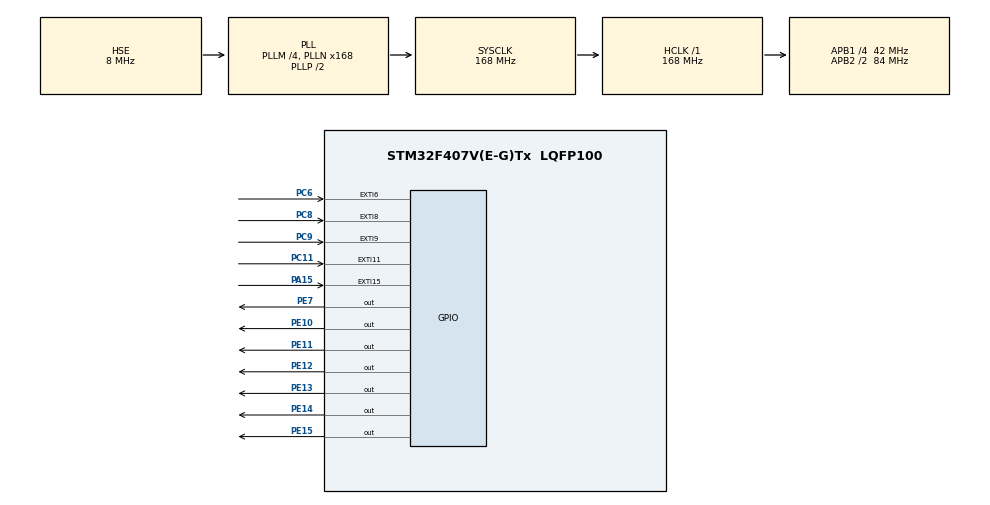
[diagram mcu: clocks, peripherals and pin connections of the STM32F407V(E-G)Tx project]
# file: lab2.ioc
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Mcu.Family=STM32F4
Mcu.Name=STM32F407V(E-G)Tx
Mcu.Package=LQFP100
NVIC.EXTI15_10_IRQn=true\:0\:0\:false\:false\:true\:true\:true
NVIC.EXTI9_5_IRQn=true\:0\:0\:false\:false\:true\:true\:true
NVIC.PriorityGroup=NVIC_PRIORITYGROUP_4
PA15.GPIO_ModeDefaultEXTI=GPIO_MODE_IT_FALLING
PA15.Signal=GPXTI15
PC11.GPIO_ModeDefaultEXTI=GPIO_MODE_IT_FALLING
PC11.Signal=GPXTI11
PC6.GPIO_ModeDefaultEXTI=GPIO_MODE_IT_FALLING
PC6.Signal=GPXTI6
PC8.GPIO_ModeDefaultEXTI=GPIO_MODE_IT_FALLING
PC8.Signal=GPXTI8
PC9.GPIO_ModeDefaultEXTI=GPIO_MODE_IT_FALLING
PC9.Signal=GPXTI9
PE10.Signal=GPIO_Output
PE11.Signal=GPIO_Output
PE12.Signal=GPIO_Output
PE13.Signal=GPIO_Output
PE14.Signal=GPIO_Output
PE15.Signal=GPIO_Output
PE7.Signal=GPIO_Output
PH0-OSC_IN.Mode=HSE-External-Oscillator
PH0-OSC_IN.Signal=RCC_OSC_IN
PH1-OSC_OUT.Mode=HSE-External-Oscillator
PH1-OSC_OUT.Signal=RCC_OSC_OUT
ProjectManager.HeapSize=0x200
ProjectManager.StackSize=0x400
ProjectManager.TargetToolchain=MDK-ARM V5.27
RCC.48MHZClocksFreq_Value=84000000
RCC.AHBFreq_Value=168000000
RCC.APB1CLKDivider=RCC_HCLK_DIV4
RCC.APB1Freq_Value=42000000
RCC.APB1TimFreq_Value=84000000
RCC.APB2CLKDivider=RCC_HCLK_DIV2
RCC.APB2Freq_Value=84000000
RCC.APB2TimFreq_Value=168000000
RCC.CortexFreq_Value=168000000
RCC.HCLKFreq_Value=168000000
RCC.HSE_VALUE=8000000
RCC.HSI_VALUE=16000000
RCC.LSE_VALUE=32768
RCC.PLLM=4
RCC.PLLN=168
RCC.PLLSourceVirtual=RCC_PLLSOURCE_HSE
RCC.SYSCLKFreq_VALUE=168000000
RCC.SYSCLKSource=RCC_SYSCLKSOURCE_PLLCLK
RCC.VCOOutputFreq_Value=336000000
board=custom

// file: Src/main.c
/* USER CODE BEGIN Header */
/**
  ******************************************************************************
  * @file           : main.c
  * @brief          : Main program body
  ******************************************************************************
  * @attention
  *
  * <h2><center>&copy; Copyright (c) 2020 STMicroelectronics.
  * All rights reserved.</center></h2>
  *
  * This software component is licensed by ST under BSD 3-Clause license,
  * the "License"; You may not use this file except in compliance with the
  * License. You may obtain a copy of the License at:
  *                        opensource.org/licenses/BSD-3-Clause
  *
  ******************************************************************************
  */
/* USER CODE END Header */

#include "main.h"

/* USER CODE BEGIN Includes */
#include "lcd.h"
/* USER CODE END Includes */

/* USER CODE BEGIN PV */
uint8_t mode=0;
/* USER CODE END PV */

void SystemClock_Config(void);
static void MX_GPIO_Init(void);

int main(void)
{

  /* MCU Configuration--------------------------------------------------------*/

  /* Reset of all peripherals, Initializes the Flash interface and the Systick. */
  HAL_Init();

  /* Configure the system clock */
  SystemClock_Config();

  /* Initialize all configured peripherals */
  MX_GPIO_Init();
  /* USER CODE BEGIN 2 */
	lcdInit();
  /* USER CODE END 2 */

  /* Infinite loop */
  while (1)
  {
		if(mode!=0){
			if(mode==1){
				clear();
				LCD_string("Greetings");
				mode=0;
			}
			if(mode==2){
				clear();
				LCD_string("Hi once again");
				mode=0;
			}
			if(mode==3){
				clear();
				LCD_string("What's up?");
				mode=0;
			}
			if(mode==4){
				clear();
				LCD_string("Heah, sure");
				mode=0;
			}
			if(mode==5){
				clear();
				LCD_string("Bye");
				mode=0;
			}
		}
  }
}

void SystemClock_Config(void)
{
  RCC_OscInitTypeDef RCC_OscInitStruct = {0};
  RCC_ClkInitTypeDef RCC_ClkInitStruct = {0};

  /** Configure the main internal regulator output voltage
  */
  __HAL_RCC_PWR_CLK_ENABLE();
  __HAL_PWR_VOLTAGESCALING_CONFIG(PWR_REGULATOR_VOLTAGE_SCALE1);
  /** Initializes the CPU, AHB and APB busses clocks
  */
  RCC_OscInitStruct.OscillatorType = RCC_OSCILLATORTYPE_HSE;
  RCC_OscInitStruct.HSEState = RCC_HSE_ON;
  RCC_OscInitStruct.PLL.PLLState = RCC_PLL_ON;
  RCC_OscInitStruct.PLL.PLLSource = RCC_PLLSOURCE_HSE;
  RCC_OscInitStruct.PLL.PLLM = 4;
  RCC_OscInitStruct.PLL.PLLN = 168;
  RCC_OscInitStruct.PLL.PLLP = RCC_PLLP_DIV2;
  RCC_OscInitStruct.PLL.PLLQ = 4;
  if (HAL_RCC_OscConfig(&RCC_OscInitStruct) != HAL_OK)
  {
    Error_Handler();
  }
  /** Initializes the CPU, AHB and APB busses clocks
  */
  RCC_ClkInitStruct.ClockType = RCC_CLOCKTYPE_HCLK|RCC_CLOCKTYPE_SYSCLK
                              |RCC_CLOCKTYPE_PCLK1|RCC_CLOCKTYPE_PCLK2;
  RCC_ClkInitStruct.SYSCLKSource = RCC_SYSCLKSOURCE_PLLCLK;
  RCC_ClkInitStruct.AHBCLKDivider = RCC_SYSCLK_DIV1;
  RCC_ClkInitStruct.APB1CLKDivider = RCC_HCLK_DIV4;
  RCC_ClkInitStruct.APB2CLKDivider = RCC_HCLK_DIV2;

  if (HAL_RCC_ClockConfig(&RCC_ClkInitStruct, FLASH_LATENCY_5) != HAL_OK)
  {
    Error_Handler();
  }
}

static void MX_GPIO_Init(void)
{
  GPIO_InitTypeDef GPIO_InitStruct = {0};

  /* GPIO Ports Clock Enable */
  __HAL_RCC_GPIOH_CLK_ENABLE();
  __HAL_RCC_GPIOE_CLK_ENABLE();
  __HAL_RCC_GPIOC_CLK_ENABLE();
  __HAL_RCC_GPIOA_CLK_ENABLE();

  /*Configure GPIO pin Output Level */
  HAL_GPIO_WritePin(GPIOE, GPIO_PIN_7|GPIO_PIN_10|GPIO_PIN_11|GPIO_PIN_12
                          |GPIO_PIN_13|GPIO_PIN_14|GPIO_PIN_15, GPIO_PIN_RESET);

  /*Configure GPIO pins : PE7 PE10 PE11 PE12
                           PE13 PE14 PE15 */
  GPIO_InitStruct.Pin = GPIO_PIN_7|GPIO_PIN_10|GPIO_PIN_11|GPIO_PIN_12
                          |GPIO_PIN_13|GPIO_PIN_14|GPIO_PIN_15;
  GPIO_InitStruct.Mode = GPIO_MODE_OUTPUT_PP;
  GPIO_InitStruct.Pull = GPIO_NOPULL;
  GPIO_InitStruct.Speed = GPIO_SPEED_FREQ_LOW;
  HAL_GPIO_Init(GPIOE, &GPIO_InitStruct);

  /*Configure GPIO pins : PC6 PC8 PC9 PC11 */
  GPIO_InitStruct.Pin = GPIO_PIN_6|GPIO_PIN_8|GPIO_PIN_9|GPIO_PIN_11;
  GPIO_InitStruct.Mode = GPIO_MODE_IT_FALLING;
  GPIO_InitStruct.Pull = GPIO_NOPULL;
  HAL_GPIO_Init(GPIOC, &GPIO_InitStruct);

  /*Configure GPIO pin : PA15 */
  GPIO_InitStruct.Pin = GPIO_PIN_15;
  GPIO_InitStruct.Mode = GPIO_MODE_IT_FALLING;
  GPIO_InitStruct.Pull = GPIO_NOPULL;
  HAL_GPIO_Init(GPIOA, &GPIO_InitStruct);

  /* EXTI interrupt init*/
  HAL_NVIC_SetPriority(EXTI9_5_IRQn, 0, 0);
  HAL_NVIC_EnableIRQ(EXTI9_5_IRQn);

  HAL_NVIC_SetPriority(EXTI15_10_IRQn, 0, 0);
  HAL_NVIC_EnableIRQ(EXTI15_10_IRQn);

}

/* USER CODE BEGIN 4 */
void HAL_GPIO_EXTI_Callback(uint16_t GPIO_Pin)
{
  if(GPIO_Pin== GPIO_PIN_6) {
    mode=1;
  }
if(GPIO_Pin== GPIO_PIN_8) {
		mode=2;
  }
if(GPIO_Pin== GPIO_PIN_9) {
  mode=3;
  }
if(GPIO_Pin== GPIO_PIN_11) {
  mode=4;
  }
if(GPIO_Pin== GPIO_PIN_15) {
  mode=5;
  }
}
/* USER CODE END 4 */

void Error_Handler(void)
{
}

/************************ (C) COPYRIGHT STMicroelectronics *****END OF FILE****/
